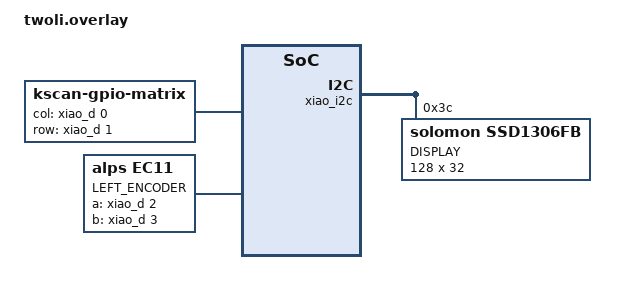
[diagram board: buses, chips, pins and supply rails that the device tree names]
#include "twoli.dtsi"

/ {
    chosen {
        zmk,kscan = &kscan0;
    };

    kscan0: kscan_0 {
        compatible = "zmk,kscan-gpio-matrix";
        label = "KSCAN";
        diode-direction = "col2row";

        col-gpios
            = <&xiao_d 0 GPIO_ACTIVE_HIGH>
            ;

        row-gpios
            = <&xiao_d 1 (GPIO_ACTIVE_HIGH | GPIO_PULL_DOWN)>
            ;
    };
    
    left_encoder: encoder_left {
		compatible = "alps,ec11";
		label = "LEFT_ENCODER";
		a-gpios = <&xiao_d 2 (GPIO_ACTIVE_HIGH | GPIO_PULL_UP)>;
		b-gpios = <&xiao_d 3 (GPIO_ACTIVE_HIGH | GPIO_PULL_UP)>;
		resolution = <4>;
		status = "okay";
	};
    
    sensors {
		compatible = "zmk,keymap-sensors";
		sensors = <&left_encoder>;
	};

};

&xiao_i2c {
	status = "okay";

	oled: ssd1306@3c {
        compatible = "solomon,ssd1306fb";
        reg = <0x3c>;
        label = "DISPLAY";
        width = <128>;
        height = <32>;
        segment-offset = <0>;
        page-offset = <0>;
        display-offset = <0>;
        multiplex-ratio = <31>;
        segment-remap;
        com-invdir;
        com-sequential;
        prechargep = <0x22>;
	};
};
